# pma_tx_lane_registers: IP-XACT component
VLNV cadence:cdns_lib:pma_tx_lane_registers:1685-2009

## Address spaces and blocks
sd3101_t4_registers.sd3101_phy_registers: base 0x10000, range 0x7ff, width 32

## Registers
Registers are 32-bit, read-write, reset 0x0 unless marked. A register's access mark holds for its fields unless they carry their own. Offsets are from the block's base; lines under a group give offsets from that group; [hi:lo] are bit positions; {n}, {i} and the like mark numbered series; 'fields as' and 'values as' point back to an identical list; <NAME> marks a mode.

## sd3101_t4_registers.sd3101_phy_registers
Base 0x00010000
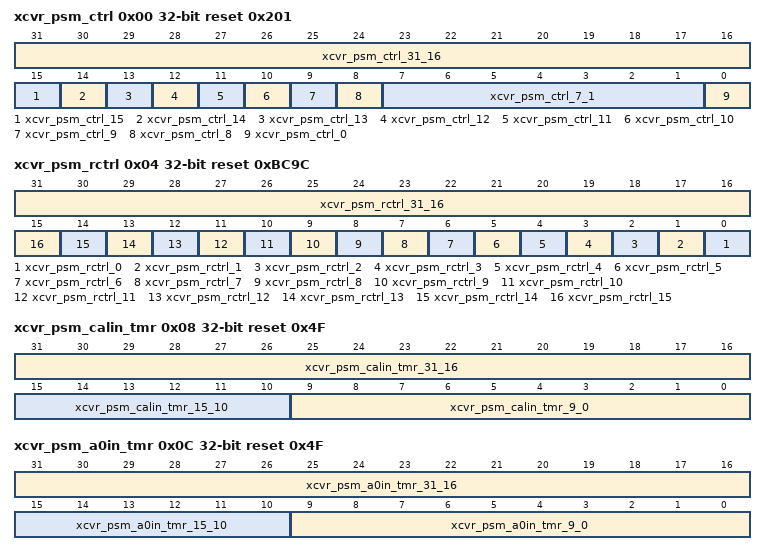
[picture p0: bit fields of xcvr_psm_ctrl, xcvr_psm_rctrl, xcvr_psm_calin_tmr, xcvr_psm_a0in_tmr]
0x00 xcvr_psm_ctrl reset 0x201 — Power state machine control register
  [31:16] xcvr_psm_ctrl_31_16 ro — Reserved
  [15] xcvr_psm_ctrl_15 ro — Reserved
  [14] xcvr_psm_ctrl_14
  [13] xcvr_psm_ctrl_13 — Bypass A0 in delay from A5
  [12] xcvr_psm_ctrl_12 — Bypass A0 in delay from A4
  [11] xcvr_psm_ctrl_11
  [10] xcvr_psm_ctrl_10 — Bypass A0 in delay from A2
  [9] xcvr_psm_ctrl_9 — Bypass A0 in delay from A1
  [8] xcvr_psm_ctrl_8 ro — Reserved
  [7:1] xcvr_psm_ctrl_7_1 ro — Reserved
  [0] xcvr_psm_ctrl_0
0x04 xcvr_psm_rctrl reset 0xBC9C — Power state machine reset control register
  [31:16] xcvr_psm_rctrl_31_16 ro — Reserved
  [n] xcvr_psm_rctrl_{n} (n=0..15)
0x08 xcvr_psm_calin_tmr reset 0x4F — PSM calibration in delay timer register
  [31:16] xcvr_psm_calin_tmr_31_16 ro — Reserved
  [15:10] xcvr_psm_calin_tmr_15_10 ro — Reserved
  [9:0] xcvr_psm_calin_tmr_9_0 — Note, the smallest value this field is allowed to be is 12'h001. With that said, setting this field to a value smaller than the reset value will likely result in incorrect function.
0x0C xcvr_psm_a0in_tmr reset 0x4F — A0 in delay timer register
  [31:16] xcvr_psm_a0in_tmr_31_16 ro — Reserved
  [15:10] xcvr_psm_a0in_tmr_15_10 ro — Reserved
  [9:0] xcvr_psm_a0in_tmr_9_0 — Note, the smallest value this field is allowed to be is 12'h001. With that said, setting this field to a value smaller than the reset value will likely result in incorrect function.
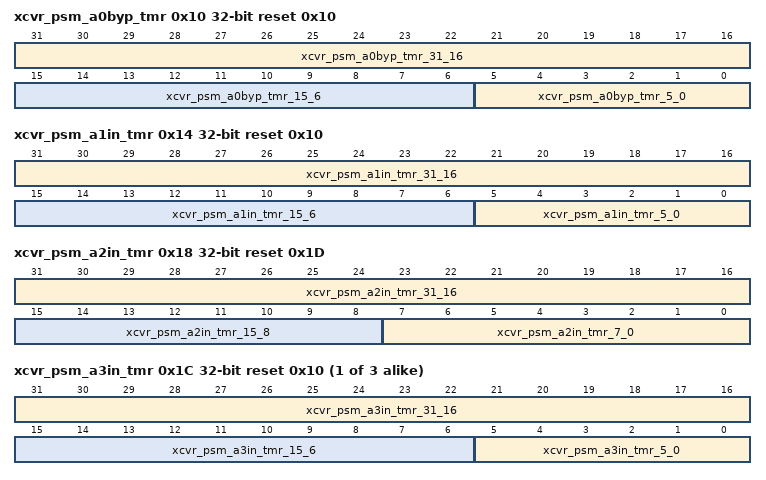
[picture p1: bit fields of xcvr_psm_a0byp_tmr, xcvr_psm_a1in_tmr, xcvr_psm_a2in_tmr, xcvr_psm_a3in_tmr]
0x10 xcvr_psm_a0byp_tmr reset 0x10 — A0 in bypass timer register
  [31:16] xcvr_psm_a0byp_tmr_31_16 ro — Reserved
  [15:6] xcvr_psm_a0byp_tmr_15_6 ro — Reserved
  [5:0] xcvr_psm_a0byp_tmr_5_0 — Note, the smallest value this field is allowed to be is 6'h01. With that said, setting this field to a value smaller than the reset value will likely result in incorrect function.
0x14 xcvr_psm_a1in_tmr reset 0x10 — A1 in delay timer register
  [31:16] xcvr_psm_a1in_tmr_31_16 ro — Reserved
  [15:6] xcvr_psm_a1in_tmr_15_6 ro — Reserved
  [5:0] xcvr_psm_a1in_tmr_5_0 — Note, the smallest value this field is allowed to be is 6'h01. With that said, setting this field to a value smaller than the reset value will likely result in incorrect function.
0x18 xcvr_psm_a2in_tmr reset 0x1D — A2 in delay timer register
  [31:16] xcvr_psm_a2in_tmr_31_16 ro — Reserved
  [15:8] xcvr_psm_a2in_tmr_15_8 ro — Reserved
  [7:0] xcvr_psm_a2in_tmr_7_0 — Note, the smallest value this field is allowed to be is 6'h01. With that said, setting this field to a value smaller than the reset value will likely result in incorrect function.
{0x10+4i} xcvr_psm_a{i}in_tmr reset 0x10 (i=3..5) — A{i} in delay timer register
  [31:16] xcvr_psm_a{i}in_tmr_31_16 ro — Reserved
  [15:6] xcvr_psm_a{i}in_tmr_15_6 ro — Reserved
  [5:0] xcvr_psm_a{i}in_tmr_5_0 — Note, the smallest value this field is allowed to be is 6'h01. With that said, setting this field to a value smaller than the reset value will likely result in incorrect function.
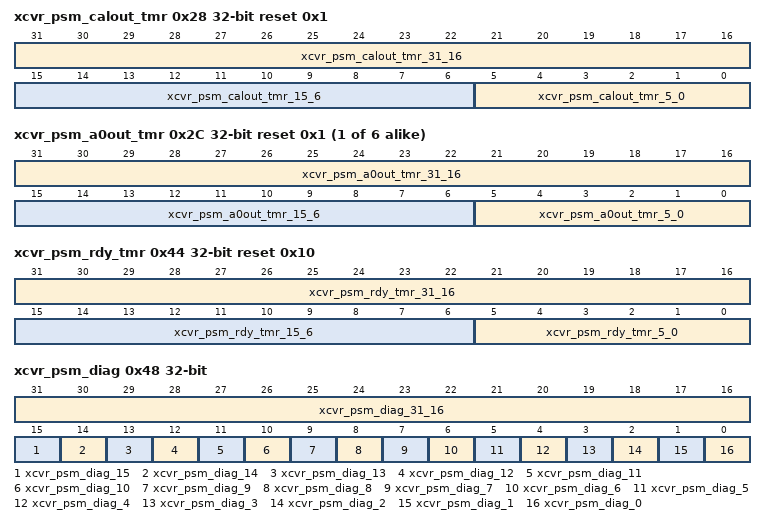
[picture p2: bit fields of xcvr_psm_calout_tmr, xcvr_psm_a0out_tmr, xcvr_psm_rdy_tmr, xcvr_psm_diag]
0x28 xcvr_psm_calout_tmr reset 0x1 — PSM calibration out delay timer register
  [31:16] xcvr_psm_calout_tmr_31_16 ro — Reserved
  [15:6] xcvr_psm_calout_tmr_15_6 ro — Reserved
  [5:0] xcvr_psm_calout_tmr_5_0 — Note, the smallest value this field is allowed to be is 6'h01. With that said, setting this field to a value smaller than the reset value will likely result in incorrect function.
{0x2C+4i} xcvr_psm_a{i}out_tmr reset 0x1 (i=0..5) — A{i} out delay timer register
  [31:16] xcvr_psm_a{i}out_tmr_31_16 ro — Reserved
  [15:6] xcvr_psm_a{i}out_tmr_15_6 ro — Reserved
  [5:0] xcvr_psm_a{i}out_tmr_5_0 — Note, the smallest value this field is allowed to be is 6'h01. With that said, setting this field to a value smaller than the reset value will likely result in incorrect function.
0x44 xcvr_psm_rdy_tmr reset 0x10 — Ready delay timer register
  [31:16] xcvr_psm_rdy_tmr_31_16 ro — Reserved
  [15:6] xcvr_psm_rdy_tmr_15_6 ro — Reserved
  [5:0] xcvr_psm_rdy_tmr_5_0 — Note, the smallest value this field is allowed to be is 6'h01. With that said, setting this field to a value smaller than the reset value will likely result in incorrect function.
0x48 xcvr_psm_diag — Power state machine diagnostic register
  [31:16] xcvr_psm_diag_31_16 ro — Reserved
  [15] xcvr_psm_diag_15 ro — Reserved
  [14] xcvr_psm_diag_14
  [13] xcvr_psm_diag_13 — Force A5 exit acknowledge
  [12] xcvr_psm_diag_12 — Force A4 exit acknowledge
  [11] xcvr_psm_diag_11
  [10] xcvr_psm_diag_10 — Force A2 exit acknowledge
  [9] xcvr_psm_diag_9 — Force A1 exit acknowledge
  [8] xcvr_psm_diag_8
  [7] xcvr_psm_diag_7 ro — Reserved
  [6] xcvr_psm_diag_6 — Force calibration entry acknowledge
  [5] xcvr_psm_diag_5 — Force A5 entry acknowledge
  [4] xcvr_psm_diag_4
  [3] xcvr_psm_diag_3 — Force A3 entry acknowledge
  [2] xcvr_psm_diag_2 — Force A2 entry acknowledge
  [1] xcvr_psm_diag_1
  [0] xcvr_psm_diag_0 — Force A0 entry acknowledge
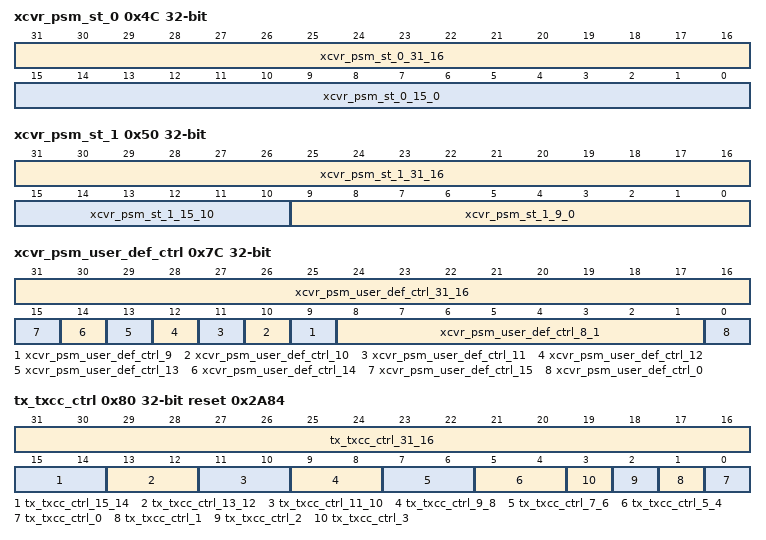
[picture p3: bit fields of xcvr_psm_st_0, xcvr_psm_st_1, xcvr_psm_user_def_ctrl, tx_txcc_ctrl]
0x4C xcvr_psm_st_0 — PSM current state register 0
  [31:16] xcvr_psm_st_0_31_16 ro — Reserved
  [15:0] xcvr_psm_st_0_15_0 ro — PSM current state[15:0]
0x50 xcvr_psm_st_1 — PSM current state register 1
  [31:16] xcvr_psm_st_1_31_16 ro — Reserved
  [15:10] xcvr_psm_st_1_15_10 ro — Reserved
  [9:0] xcvr_psm_st_1_9_0 ro — PSM current state[25:16]
0x7C xcvr_psm_user_def_ctrl — Power state machine user defined control register
  [31:16] xcvr_psm_user_def_ctrl_31_16 — Reserved - spare
  [n] xcvr_psm_user_def_ctrl_{n} (n=9..15)
  [8:1] xcvr_psm_user_def_ctrl_8_1 — Reserved - spare
  [0] xcvr_psm_user_def_ctrl_0
0x80 tx_txcc_ctrl reset 0x2A84 — TX coefficient controller control register
  [31:16] tx_txcc_ctrl_31_16 ro — Reserved
  [15:14] tx_txcc_ctrl_15_14 ro — Reserved
  [13:12] tx_txcc_ctrl_13_12
  [11:10] tx_txcc_ctrl_11_10
  [9:8] tx_txcc_ctrl_9_8
  [7:6] tx_txcc_ctrl_7_6
  [5:4] tx_txcc_ctrl_5_4
  [n] tx_txcc_ctrl_{n} (n=0..3)
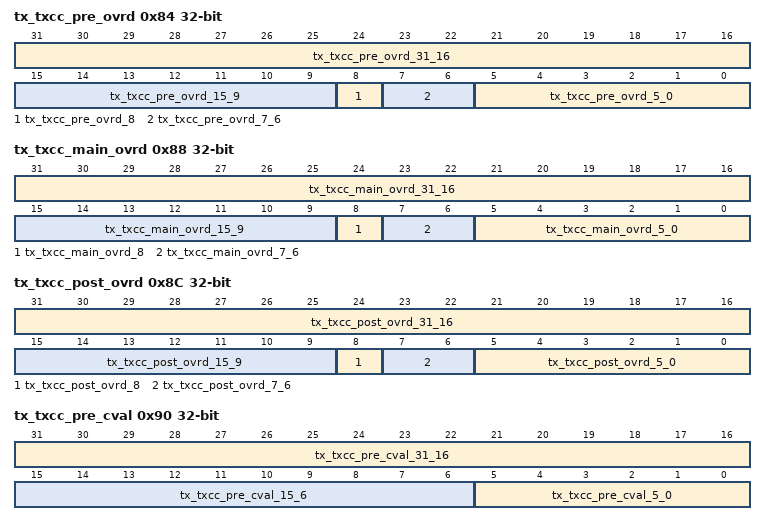
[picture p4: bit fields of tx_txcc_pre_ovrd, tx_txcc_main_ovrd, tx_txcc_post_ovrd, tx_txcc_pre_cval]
0x84 tx_txcc_pre_ovrd — TX pre-cursor override register
  [31:16] tx_txcc_pre_ovrd_31_16 ro — Reserved
  [15:9] tx_txcc_pre_ovrd_15_9 ro — Reserved
  [8] tx_txcc_pre_ovrd_8 — Pre-cursor override enable
  [7:6] tx_txcc_pre_ovrd_7_6 ro — Reserved
  [5:0] tx_txcc_pre_ovrd_5_0
0x88 tx_txcc_main_ovrd — TX main-cursor override register
  [31:16] tx_txcc_main_ovrd_31_16 ro — Reserved
  [15:9] tx_txcc_main_ovrd_15_9 ro — Reserved
  [8] tx_txcc_main_ovrd_8 — Main-cursor override enable
  [7:6] tx_txcc_main_ovrd_7_6 ro — Reserved
  [5:0] tx_txcc_main_ovrd_5_0
0x8C tx_txcc_post_ovrd — TX post-cursor override register
  [31:16] tx_txcc_post_ovrd_31_16 ro — Reserved
  [15:9] tx_txcc_post_ovrd_15_9 ro — Reserved
  [8] tx_txcc_post_ovrd_8 — Post-cursor override enable
  [7:6] tx_txcc_post_ovrd_7_6 ro — Reserved
  [5:0] tx_txcc_post_ovrd_5_0
0x90 tx_txcc_pre_cval — TX pre-cursor current value register
  [31:16] tx_txcc_pre_cval_31_16 ro — Reserved
  [15:6] tx_txcc_pre_cval_15_6 ro — Reserved
  [5:0] tx_txcc_pre_cval_5_0 ro
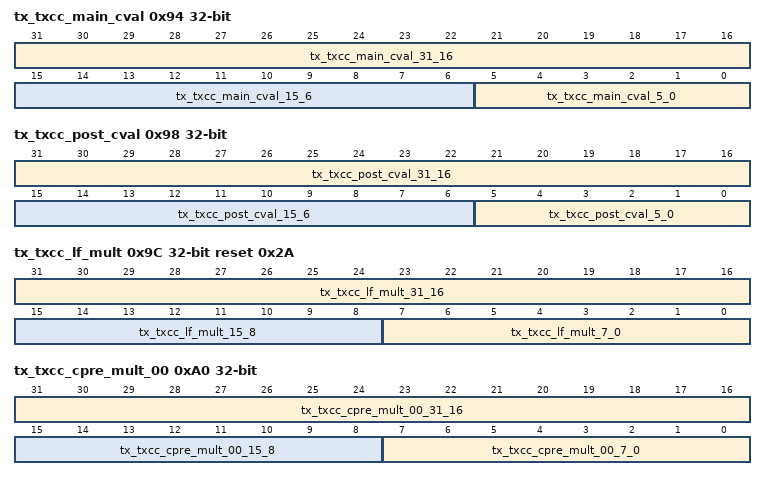
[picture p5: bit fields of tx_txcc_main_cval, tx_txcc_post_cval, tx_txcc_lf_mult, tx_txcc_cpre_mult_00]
0x94 tx_txcc_main_cval — TX main-cursor current value register
  [31:16] tx_txcc_main_cval_31_16 ro — Reserved
  [15:6] tx_txcc_main_cval_15_6 ro — Reserved
  [5:0] tx_txcc_main_cval_5_0 ro
0x98 tx_txcc_post_cval — TX post-cursor current value register
  [31:16] tx_txcc_post_cval_31_16 ro — Reserved
  [15:6] tx_txcc_post_cval_15_6 ro — Reserved
  [5:0] tx_txcc_post_cval_5_0 ro
0x9C tx_txcc_lf_mult reset 0x2A — LF multiplier value register
  [31:16] tx_txcc_lf_mult_31_16 ro — Reserved
  [15:8] tx_txcc_lf_mult_15_8 ro — Reserved
  [7:0] tx_txcc_lf_mult_7_0 — Note: The output of the multiplier is 6 bits wide. It is possible to set the multiplier value here to a sufficiently large value to cause the multiplier result to be such that it can't be represented by a 6 bit value. In such a case, the multiplier output will be driven to 6'b111111.
0xA0 tx_txcc_cpre_mult_00 — Calculated pre emphasis multiplier value 00 register
  [31:16] tx_txcc_cpre_mult_00_31_16 ro — Reserved
  [15:8] tx_txcc_cpre_mult_00_15_8 ro — Reserved
  [7:0] tx_txcc_cpre_mult_00_7_0 — Note: The output of the multiplier is 6 bits wide. It is possible to set the multiplier value here to a sufficiently large value to cause the multiplier result to be such that it can't be represented by a 6 bit value. In such a case, the multiplier output will be driven to 6'b111111.
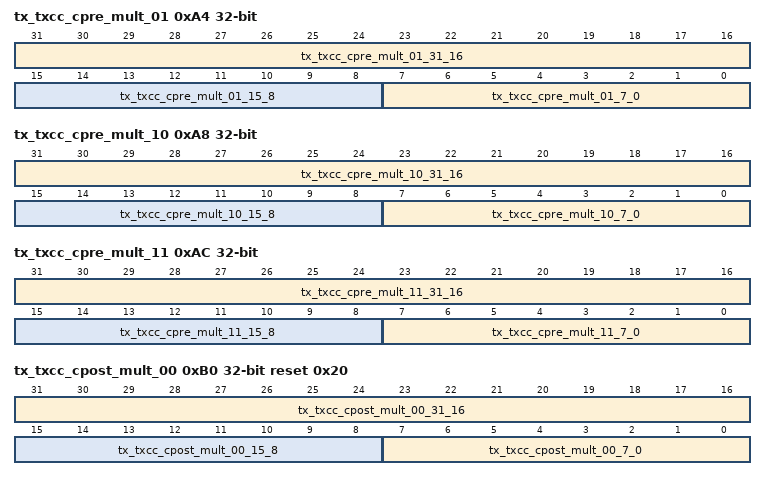
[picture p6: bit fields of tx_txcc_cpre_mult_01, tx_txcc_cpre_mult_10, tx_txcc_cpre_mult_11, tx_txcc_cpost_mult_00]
0xA4 tx_txcc_cpre_mult_01 — Calculated pre emphasis multiplier value 01 register
  [31:16] tx_txcc_cpre_mult_01_31_16 ro — Reserved
  [15:8] tx_txcc_cpre_mult_01_15_8 ro — Reserved
  [7:0] tx_txcc_cpre_mult_01_7_0 — Note: The output of the multiplier is 6 bits wide. It is possible to set the multiplier value here to a sufficiently large value to cause the multiplier result to be such that it can't be represented by a 6 bit value. In such a case, the multiplier output will be driven to 6'b111111.
0xA8 tx_txcc_cpre_mult_10 — Calculated pre emphasis multiplier value 10 register
  [31:16] tx_txcc_cpre_mult_10_31_16 ro — Reserved
  [15:8] tx_txcc_cpre_mult_10_15_8 ro — Reserved
  [7:0] tx_txcc_cpre_mult_10_7_0 — Note: The output of the multiplier is 6 bits wide. It is possible to set the multiplier value here to a sufficiently large value to cause the multiplier result to be such that it can't be represented by a 6 bit value. In such a case, the multiplier output will be driven to 6'b111111.
0xAC tx_txcc_cpre_mult_11 — Calculated pre emphasis multiplier value 11 register
  [31:16] tx_txcc_cpre_mult_11_31_16 ro — Reserved
  [15:8] tx_txcc_cpre_mult_11_15_8 ro — Reserved
  [7:0] tx_txcc_cpre_mult_11_7_0 — Note: The output of the multiplier is 6 bits wide. It is possible to set the multiplier value here to a sufficiently large value to cause the multiplier result to be such that it can't be represented by a 6 bit value. In such a case, the multiplier output will be driven to 6'b111111.
0xB0 tx_txcc_cpost_mult_00 reset 0x20 — Calculated post emphasis multiplier value 00 register
  [31:16] tx_txcc_cpost_mult_00_31_16 ro — Reserved
  [15:8] tx_txcc_cpost_mult_00_15_8 ro — Reserved
  [7:0] tx_txcc_cpost_mult_00_7_0 — Note: The output of the multiplier is 6 bits wide. It is possible to set the multiplier value here to a sufficiently large value to cause the multiplier result to be such that it can't be represented by a 6 bit value. In such a case, the multiplier output will be driven to 6'b111111.
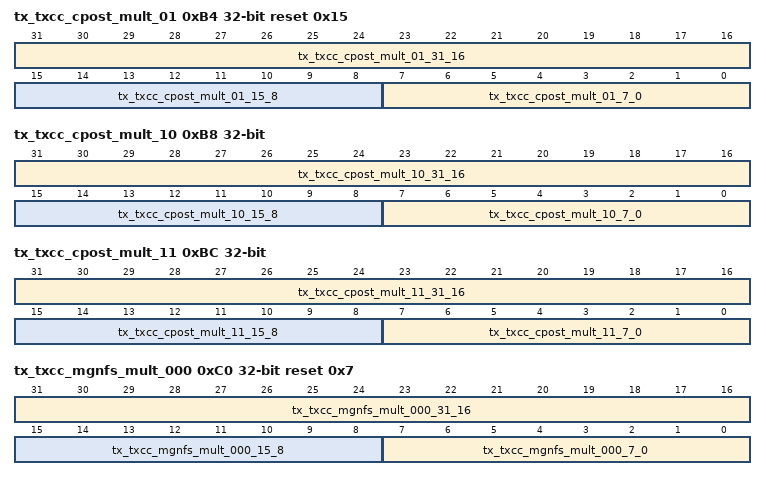
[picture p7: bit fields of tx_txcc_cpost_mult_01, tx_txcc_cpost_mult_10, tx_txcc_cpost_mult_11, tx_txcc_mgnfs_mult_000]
0xB4 tx_txcc_cpost_mult_01 reset 0x15 — Calculated post emphasis multiplier value 01 register
  [31:16] tx_txcc_cpost_mult_01_31_16 ro — Reserved
  [15:8] tx_txcc_cpost_mult_01_15_8 ro — Reserved
  [7:0] tx_txcc_cpost_mult_01_7_0 — Note: The output of the multiplier is 6 bits wide. It is possible to set the multiplier value here to a sufficiently large value to cause the multiplier result to be such that it can't be represented by a 6 bit value. In such a case, the multiplier output will be driven to 6'b111111.
0xB8 tx_txcc_cpost_mult_10 — Calculated post emphasis multiplier value 10 register
  [31:16] tx_txcc_cpost_mult_10_31_16 ro — Reserved
  [15:8] tx_txcc_cpost_mult_10_15_8 ro — Reserved
  [7:0] tx_txcc_cpost_mult_10_7_0 — Note: The output of the multiplier is 6 bits wide. It is possible to set the multiplier value here to a sufficiently large value to cause the multiplier result to be such that it can't be represented by a 6 bit value. In such a case, the multiplier output will be driven to 6'b111111.
0xBC tx_txcc_cpost_mult_11 — Calculated post emphasis multiplier value 11 register
  [31:16] tx_txcc_cpost_mult_11_31_16 ro — Reserved
  [15:8] tx_txcc_cpost_mult_11_15_8 ro — Reserved
  [7:0] tx_txcc_cpost_mult_11_7_0 — Note: The output of the multiplier is 6 bits wide. It is possible to set the multiplier value here to a sufficiently large value to cause the multiplier result to be such that it can't be represented by a 6 bit value. In such a case, the multiplier output will be driven to 6'b111111.
0xC0 tx_txcc_mgnfs_mult_000 reset 0x7 — Margin full swing multiplier value 000 register
  [31:16] tx_txcc_mgnfs_mult_000_31_16 ro — Reserved
  [15:8] tx_txcc_mgnfs_mult_000_15_8 ro — Reserved
  [7:0] tx_txcc_mgnfs_mult_000_7_0 — Note: The output of the multiplier is 6 bits wide. It is possible to set the multiplier value here to a sufficiently large value to cause the multiplier result to be such that it can't be represented by a 6 bit value. In such a case, the multiplier output will be driven to 6'b111111.
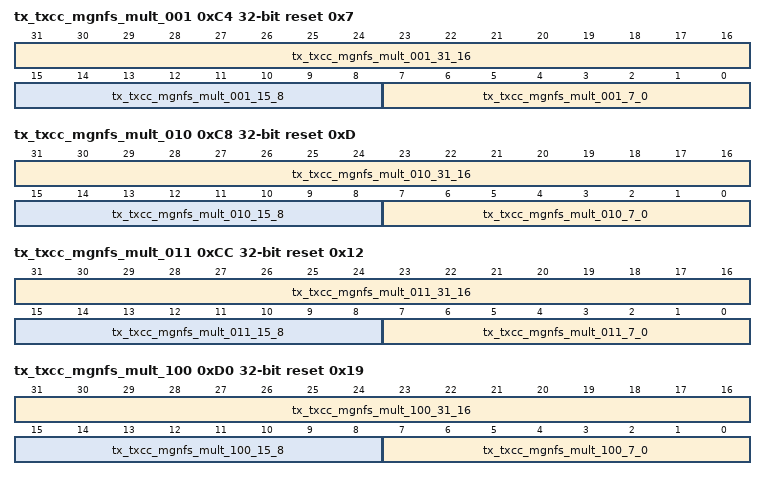
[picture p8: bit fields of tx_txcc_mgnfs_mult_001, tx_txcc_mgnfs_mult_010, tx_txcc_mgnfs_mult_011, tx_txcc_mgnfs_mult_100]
0xC4 tx_txcc_mgnfs_mult_001 reset 0x7 — Margin full swing multiplier value 001 register
  [31:16] tx_txcc_mgnfs_mult_001_31_16 ro — Reserved
  [15:8] tx_txcc_mgnfs_mult_001_15_8 ro — Reserved
  [7:0] tx_txcc_mgnfs_mult_001_7_0 — Note: The output of the multiplier is 6 bits wide. It is possible to set the multiplier value here to a sufficiently large value to cause the multiplier result to be such that it can't be represented by a 6 bit value. In such a case, the multiplier output will be driven to 6'b111111.
0xC8 tx_txcc_mgnfs_mult_010 reset 0xD — Margin full swing multiplier value 010 register
  [31:16] tx_txcc_mgnfs_mult_010_31_16 ro — Reserved
  [15:8] tx_txcc_mgnfs_mult_010_15_8 ro — Reserved
  [7:0] tx_txcc_mgnfs_mult_010_7_0 — Note: The output of the multiplier is 6 bits wide. It is possible to set the multiplier value here to a sufficiently large value to cause the multiplier result to be such that it can't be represented by a 6 bit value. In such a case, the multiplier output will be driven to 6'b111111.
0xCC tx_txcc_mgnfs_mult_011 reset 0x12 — Margin full swing multiplier value 011 register
  [31:16] tx_txcc_mgnfs_mult_011_31_16 ro — Reserved
  [15:8] tx_txcc_mgnfs_mult_011_15_8 ro — Reserved
  [7:0] tx_txcc_mgnfs_mult_011_7_0 — Note: The output of the multiplier is 6 bits wide. It is possible to set the multiplier value here to a sufficiently large value to cause the multiplier result to be such that it can't be represented by a 6 bit value. In such a case, the multiplier output will be driven to 6'b111111.
0xD0 tx_txcc_mgnfs_mult_100 reset 0x19 — Margin full swing multiplier value 100 register
  [31:16] tx_txcc_mgnfs_mult_100_31_16 ro — Reserved
  [15:8] tx_txcc_mgnfs_mult_100_15_8 ro — Reserved
  [7:0] tx_txcc_mgnfs_mult_100_7_0 — Note: The output of the multiplier is 6 bits wide. It is possible to set the multiplier value here to a sufficiently large value to cause the multiplier result to be such that it can't be represented by a 6 bit value. In such a case, the multiplier output will be driven to 6'b111111.
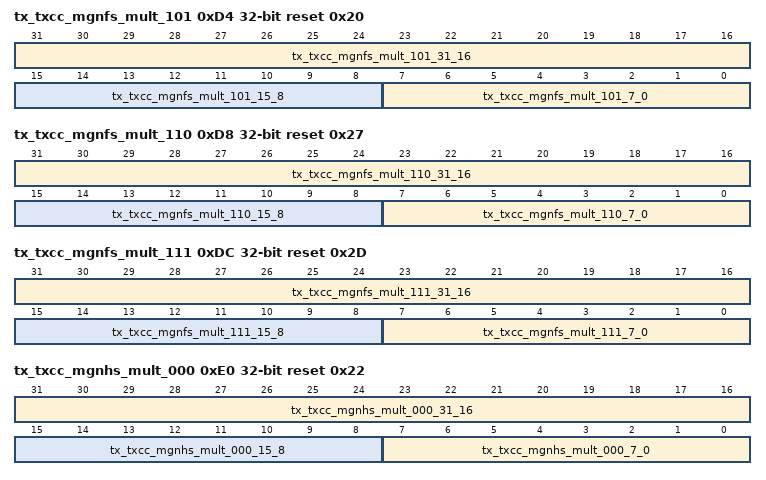
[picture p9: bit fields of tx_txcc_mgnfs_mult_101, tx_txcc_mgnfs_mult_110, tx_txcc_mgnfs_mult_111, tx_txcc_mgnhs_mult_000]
0xD4 tx_txcc_mgnfs_mult_101 reset 0x20 — Margin full swing multiplier value 101 register
  [31:16] tx_txcc_mgnfs_mult_101_31_16 ro — Reserved
  [15:8] tx_txcc_mgnfs_mult_101_15_8 ro — Reserved
  [7:0] tx_txcc_mgnfs_mult_101_7_0 — Note: The output of the multiplier is 6 bits wide. It is possible to set the multiplier value here to a sufficiently large value to cause the multiplier result to be such that it can't be represented by a 6 bit value. In such a case, the multiplier output will be driven to 6'b111111.
0xD8 tx_txcc_mgnfs_mult_110 reset 0x27 — Margin full swing multiplier value 110 register
  [31:16] tx_txcc_mgnfs_mult_110_31_16 ro — Reserved
  [15:8] tx_txcc_mgnfs_mult_110_15_8 ro — Reserved
  [7:0] tx_txcc_mgnfs_mult_110_7_0 — Note: The output of the multiplier is 6 bits wide. It is possible to set the multiplier value here to a sufficiently large value to cause the multiplier result to be such that it can't be represented by a 6 bit value. In such a case, the multiplier output will be driven to 6'b111111.
0xDC tx_txcc_mgnfs_mult_111 reset 0x2D — Margin full swing multiplier value 111 register
  [31:16] tx_txcc_mgnfs_mult_111_31_16 ro — Reserved
  [15:8] tx_txcc_mgnfs_mult_111_15_8 ro — Reserved
  [7:0] tx_txcc_mgnfs_mult_111_7_0 — Note: The output of the multiplier is 6 bits wide. It is possible to set the multiplier value here to a sufficiently large value to cause the multiplier result to be such that it can't be represented by a 6 bit value. In such a case, the multiplier output will be driven to 6'b111111.
0xE0 tx_txcc_mgnhs_mult_000 reset 0x22 — Margin half swing multiplier value 000 register
  [31:16] tx_txcc_mgnhs_mult_000_31_16 ro — Reserved
  [15:8] tx_txcc_mgnhs_mult_000_15_8 ro — Reserved
  [7:0] tx_txcc_mgnhs_mult_000_7_0 — Note: The output of the multiplier is 6 bits wide. It is possible to set the multiplier value here to a sufficiently large value to cause the multiplier result to be such that it can't be represented by a 6 bit value. In such a case, the multiplier output will be driven to 6'b111111.
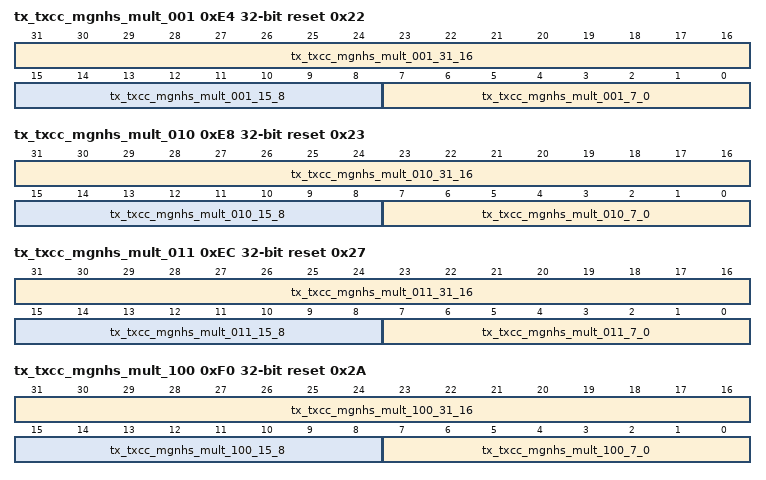
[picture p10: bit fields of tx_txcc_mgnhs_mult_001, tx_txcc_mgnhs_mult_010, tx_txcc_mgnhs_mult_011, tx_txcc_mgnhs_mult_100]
0xE4 tx_txcc_mgnhs_mult_001 reset 0x22 — Margin half swing multiplier value 001 register
  [31:16] tx_txcc_mgnhs_mult_001_31_16 ro — Reserved
  [15:8] tx_txcc_mgnhs_mult_001_15_8 ro — Reserved
  [7:0] tx_txcc_mgnhs_mult_001_7_0 — Note: The output of the multiplier is 6 bits wide. It is possible to set the multiplier value here to a sufficiently large value to cause the multiplier result to be such that it can't be represented by a 6 bit value. In such a case, the multiplier output will be driven to 6'b111111.
0xE8 tx_txcc_mgnhs_mult_010 reset 0x23 — Margin half swing multiplier value 010 register
  [31:16] tx_txcc_mgnhs_mult_010_31_16 ro — Reserved
  [15:8] tx_txcc_mgnhs_mult_010_15_8 ro — Reserved
  [7:0] tx_txcc_mgnhs_mult_010_7_0 — Note: The output of the multiplier is 6 bits wide. It is possible to set the multiplier value here to a sufficiently large value to cause the multiplier result to be such that it can't be represented by a 6 bit value. In such a case, the multiplier output will be driven to 6'b111111.
0xEC tx_txcc_mgnhs_mult_011 reset 0x27 — Margin half swing multiplier value 011 register
  [31:16] tx_txcc_mgnhs_mult_011_31_16 ro — Reserved
  [15:8] tx_txcc_mgnhs_mult_011_15_8 ro — Reserved
  [7:0] tx_txcc_mgnhs_mult_011_7_0 — Note: The output of the multiplier is 6 bits wide. It is possible to set the multiplier value here to a sufficiently large value to cause the multiplier result to be such that it can't be represented by a 6 bit value. In such a case, the multiplier output will be driven to 6'b111111.
0xF0 tx_txcc_mgnhs_mult_100 reset 0x2A — Margin half swing multiplier value 100 register
  [31:16] tx_txcc_mgnhs_mult_100_31_16 ro — Reserved
  [15:8] tx_txcc_mgnhs_mult_100_15_8 ro — Reserved
  [7:0] tx_txcc_mgnhs_mult_100_7_0 — Note: The output of the multiplier is 6 bits wide. It is possible to set the multiplier value here to a sufficiently large value to cause the multiplier result to be such that it can't be represented by a 6 bit value. In such a case, the multiplier output will be driven to 6'b111111.
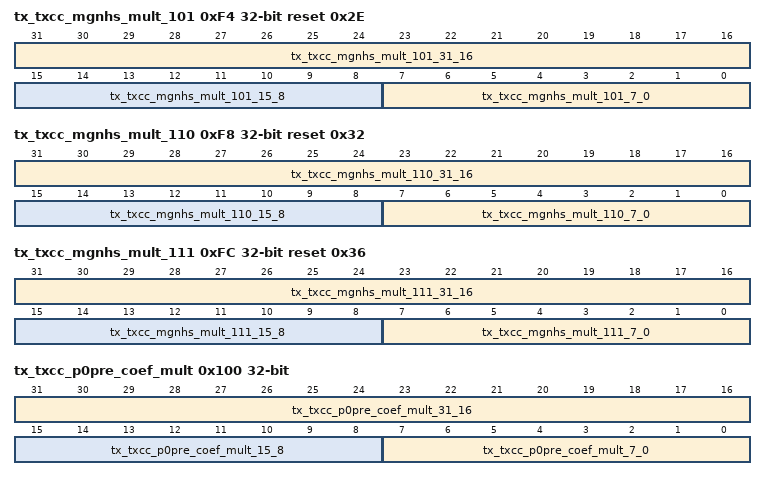
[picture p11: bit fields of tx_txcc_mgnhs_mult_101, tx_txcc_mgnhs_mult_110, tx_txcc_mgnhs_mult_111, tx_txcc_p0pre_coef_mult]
0xF4 tx_txcc_mgnhs_mult_101 reset 0x2E — Margin half swing multiplier value 101 register
  [31:16] tx_txcc_mgnhs_mult_101_31_16 ro — Reserved
  [15:8] tx_txcc_mgnhs_mult_101_15_8 ro — Reserved
  [7:0] tx_txcc_mgnhs_mult_101_7_0 — Note: The output of the multiplier is 6 bits wide. It is possible to set the multiplier value here to a sufficiently large value to cause the multiplier result to be such that it can't be represented by a 6 bit value. In such a case, the multiplier output will be driven to 6'b111111.
0xF8 tx_txcc_mgnhs_mult_110 reset 0x32 — Margin half swing multiplier value 110 register
  [31:16] tx_txcc_mgnhs_mult_110_31_16 ro — Reserved
  [15:8] tx_txcc_mgnhs_mult_110_15_8 ro — Reserved
  [7:0] tx_txcc_mgnhs_mult_110_7_0 — Note: The output of the multiplier is 6 bits wide. It is possible to set the multiplier value here to a sufficiently large value to cause the multiplier result to be such that it can't be represented by a 6 bit value. In such a case, the multiplier output will be driven to 6'b111111.
0xFC tx_txcc_mgnhs_mult_111 reset 0x36 — Margin half swing multiplier value 111 register
  [31:16] tx_txcc_mgnhs_mult_111_31_16 ro — Reserved
  [15:8] tx_txcc_mgnhs_mult_111_15_8 ro — Reserved
  [7:0] tx_txcc_mgnhs_mult_111_7_0 — Note: The output of the multiplier is 6 bits wide. It is possible to set the multiplier value here to a sufficiently large value to cause the multiplier result to be such that it can't be represented by a 6 bit value. In such a case, the multiplier output will be driven to 6'b111111.
0x100 tx_txcc_p0pre_coef_mult — Preset 0 pre emphasis coefficient multiplier value register
  [31:16] tx_txcc_p0pre_coef_mult_31_16 ro — Reserved
  [15:8] tx_txcc_p0pre_coef_mult_15_8 ro — Reserved
  [7:0] tx_txcc_p0pre_coef_mult_7_0 — Note: The output of the multiplier is 6 bits wide. It is possible to set the multiplier value here to a sufficiently large value to cause the multiplier result to be such that it can't be represented by a 6 bit value. In such a case, the multiplier output will be driven to 6'b111111.
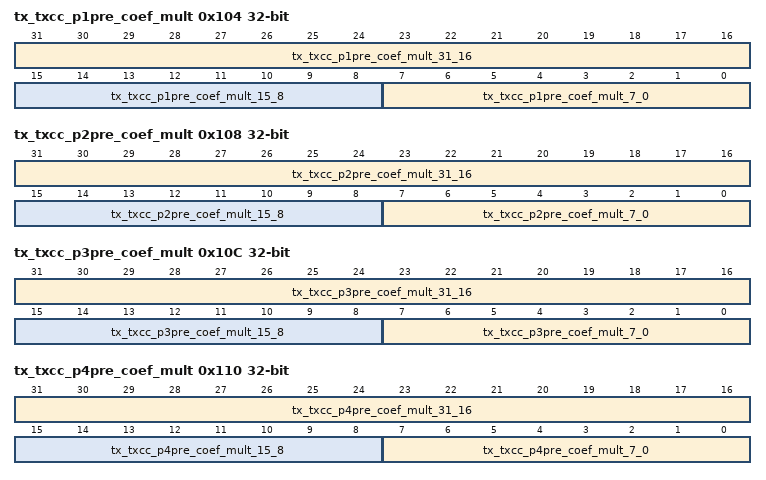
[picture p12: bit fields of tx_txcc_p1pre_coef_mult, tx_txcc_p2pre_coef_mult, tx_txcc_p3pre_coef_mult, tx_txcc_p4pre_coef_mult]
0x104 tx_txcc_p1pre_coef_mult — Preset 1 pre emphasis coefficient multiplier value register
  [31:16] tx_txcc_p1pre_coef_mult_31_16 ro — Reserved
  [15:8] tx_txcc_p1pre_coef_mult_15_8 ro — Reserved
  [7:0] tx_txcc_p1pre_coef_mult_7_0 — Note: The output of the multiplier is 6 bits wide. It is possible to set the multiplier value here to a sufficiently large value to cause the multiplier result to be such that it can't be represented by a 6 bit value. In such a case, the multiplier output will be driven to 6'b111111.
0x108 tx_txcc_p2pre_coef_mult — Preset 2 pre emphasis coefficient multiplier value register
  [31:16] tx_txcc_p2pre_coef_mult_31_16 ro — Reserved
  [15:8] tx_txcc_p2pre_coef_mult_15_8 ro — Reserved
  [7:0] tx_txcc_p2pre_coef_mult_7_0 — Note: The output of the multiplier is 6 bits wide. It is possible to set the multiplier value here to a sufficiently large value to cause the multiplier result to be such that it can't be represented by a 6 bit value. In such a case, the multiplier output will be driven to 6'b111111.
0x10C tx_txcc_p3pre_coef_mult — Preset 3 pre emphasis coefficient multiplier value register
  [31:16] tx_txcc_p3pre_coef_mult_31_16 ro — Reserved
  [15:8] tx_txcc_p3pre_coef_mult_15_8 ro — Reserved
  [7:0] tx_txcc_p3pre_coef_mult_7_0 — Note: The output of the multiplier is 6 bits wide. It is possible to set the multiplier value here to a sufficiently large value to cause the multiplier result to be such that it can't be represented by a 6 bit value. In such a case, the multiplier output will be driven to 6'b111111.
0x110 tx_txcc_p4pre_coef_mult — Preset 4 pre emphasis coefficient multiplier value register
  [31:16] tx_txcc_p4pre_coef_mult_31_16 ro — Reserved
  [15:8] tx_txcc_p4pre_coef_mult_15_8 ro — Reserved
  [7:0] tx_txcc_p4pre_coef_mult_7_0 — Note: The output of the multiplier is 6 bits wide. It is possible to set the multiplier value here to a sufficiently large value to cause the multiplier result to be such that it can't be represented by a 6 bit value. In such a case, the multiplier output will be driven to 6'b111111.
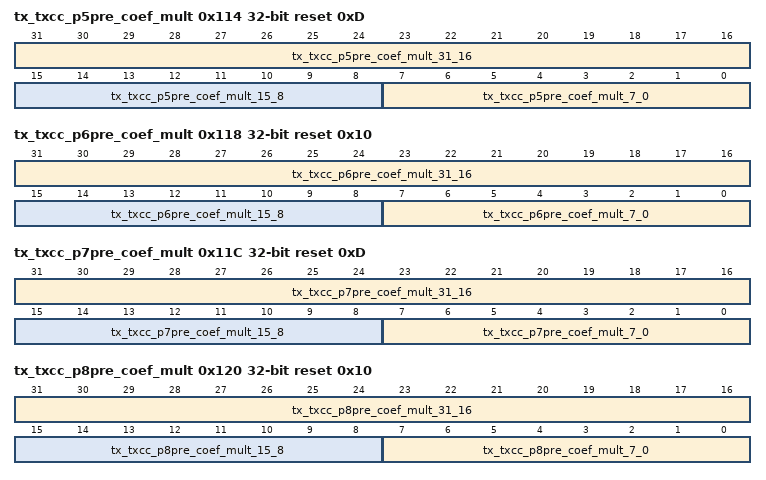
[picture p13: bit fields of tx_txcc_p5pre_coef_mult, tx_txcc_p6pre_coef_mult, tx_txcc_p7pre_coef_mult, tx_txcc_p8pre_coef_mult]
0x114 tx_txcc_p5pre_coef_mult reset 0xD — Preset 5 pre emphasis coefficient multiplier value register
  [31:16] tx_txcc_p5pre_coef_mult_31_16 ro — Reserved
  [15:8] tx_txcc_p5pre_coef_mult_15_8 ro — Reserved
  [7:0] tx_txcc_p5pre_coef_mult_7_0 — Note: The output of the multiplier is 6 bits wide. It is possible to set the multiplier value here to a sufficiently large value to cause the multiplier result to be such that it can't be represented by a 6 bit value. In such a case, the multiplier output will be driven to 6'b111111.
0x118 tx_txcc_p6pre_coef_mult reset 0x10 — Preset 6 pre emphasis coefficient multiplier value register
  [31:16] tx_txcc_p6pre_coef_mult_31_16 ro — Reserved
  [15:8] tx_txcc_p6pre_coef_mult_15_8 ro — Reserved
  [7:0] tx_txcc_p6pre_coef_mult_7_0 — Note: The output of the multiplier is 6 bits wide. It is possible to set the multiplier value here to a sufficiently large value to cause the multiplier result to be such that it can't be represented by a 6 bit value. In such a case, the multiplier output will be driven to 6'b111111.
0x11C tx_txcc_p7pre_coef_mult reset 0xD — Preset 7 pre emphasis coefficient multiplier value register
  [31:16] tx_txcc_p7pre_coef_mult_31_16 ro — Reserved
  [15:8] tx_txcc_p7pre_coef_mult_15_8 ro — Reserved
  [7:0] tx_txcc_p7pre_coef_mult_7_0 — Note: The output of the multiplier is 6 bits wide. It is possible to set the multiplier value here to a sufficiently large value to cause the multiplier result to be such that it can't be represented by a 6 bit value. In such a case, the multiplier output will be driven to 6'b111111.
0x120 tx_txcc_p8pre_coef_mult reset 0x10 — Preset 8 pre emphasis coefficient multiplier value register
  [31:16] tx_txcc_p8pre_coef_mult_31_16 ro — Reserved
  [15:8] tx_txcc_p8pre_coef_mult_15_8 ro — Reserved
  [7:0] tx_txcc_p8pre_coef_mult_7_0 — Note: The output of the multiplier is 6 bits wide. It is possible to set the multiplier value here to a sufficiently large value to cause the multiplier result to be such that it can't be represented by a 6 bit value. In such a case, the multiplier output will be driven to 6'b111111.
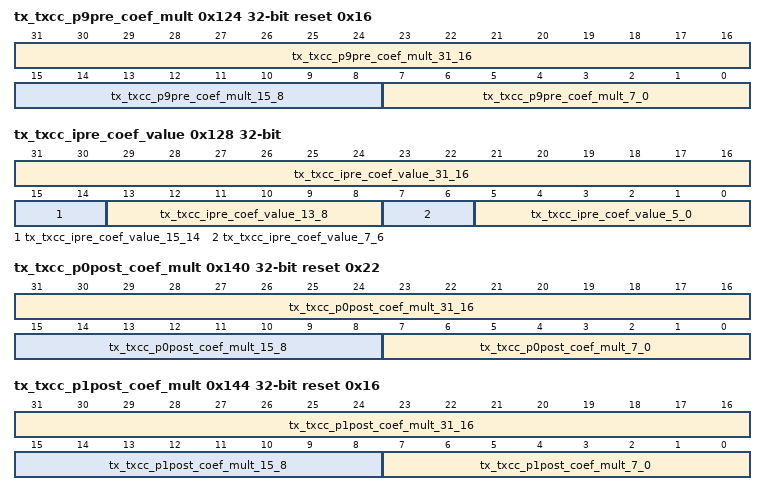
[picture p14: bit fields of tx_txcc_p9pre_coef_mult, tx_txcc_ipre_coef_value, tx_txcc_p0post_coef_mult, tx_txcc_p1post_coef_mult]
0x124 tx_txcc_p9pre_coef_mult reset 0x16 — Preset 9 pre emphasis coefficient multiplier value register
  [31:16] tx_txcc_p9pre_coef_mult_31_16 ro — Reserved
  [15:8] tx_txcc_p9pre_coef_mult_15_8 ro — Reserved
  [7:0] tx_txcc_p9pre_coef_mult_7_0 — Note: The output of the multiplier is 6 bits wide. It is possible to set the multiplier value here to a sufficiently large value to cause the multiplier result to be such that it can't be represented by a 6 bit value. In such a case, the multiplier output will be driven to 6'b111111.
0x128 tx_txcc_ipre_coef_value — Init pre emphasis coefficient value register
  [31:16] tx_txcc_ipre_coef_value_31_16 ro — Reserved
  [15:14] tx_txcc_ipre_coef_value_15_14 ro — Reserved
  [13:8] tx_txcc_ipre_coef_value_13_8
  [7:6] tx_txcc_ipre_coef_value_7_6 ro — Reserved
  [5:0] tx_txcc_ipre_coef_value_5_0
0x140 tx_txcc_p0post_coef_mult reset 0x22 — Preset 0 post emphasis coefficient multiplier value register
  [31:16] tx_txcc_p0post_coef_mult_31_16 ro — Reserved
  [15:8] tx_txcc_p0post_coef_mult_15_8 ro — Reserved
  [7:0] tx_txcc_p0post_coef_mult_7_0 — Note: The output of the multiplier is 6 bits wide. It is possible to set the multiplier value here to a sufficiently large value to cause the multiplier result to be such that it can't be represented by a 6 bit value. In such a case, the multiplier output will be driven to 6'b111111.
0x144 tx_txcc_p1post_coef_mult reset 0x16 — Preset 1 post emphasis coefficient multiplier value register
  [31:16] tx_txcc_p1post_coef_mult_31_16 ro — Reserved
  [15:8] tx_txcc_p1post_coef_mult_15_8 ro — Reserved
  [7:0] tx_txcc_p1post_coef_mult_7_0 — Note: The output of the multiplier is 6 bits wide. It is possible to set the multiplier value here to a sufficiently large value to cause the multiplier result to be such that it can't be represented by a 6 bit value. In such a case, the multiplier output will be driven to 6'b111111.
0x148 tx_txcc_p2post_coef_mult reset 0x19 — Preset 2 post emphasis coefficient multiplier value register
  [31:16] tx_txcc_p2post_coef_mult_31_16 ro — Reserved
  [15:8] tx_txcc_p2post_coef_mult_15_8 ro — Reserved
  [7:0] tx_txcc_p2post_coef_mult_7_0 — Note: The output of the multiplier is 6 bits wide. It is possible to set the multiplier value here to a sufficiently large value to cause the multiplier result to be such that it can't be represented by a 6 bit value. In such a case, the multiplier output will be driven to 6'b111111.
0x14C tx_txcc_p3post_coef_mult reset 0x10 — Preset 3 post emphasis coefficient multiplier value register
  [31:16] tx_txcc_p3post_coef_mult_31_16 ro — Reserved
  [15:8] tx_txcc_p3post_coef_mult_15_8 ro — Reserved
  [7:0] tx_txcc_p3post_coef_mult_7_0 — Note: The output of the multiplier is 6 bits wide. It is possible to set the multiplier value here to a sufficiently large value to cause the multiplier result to be such that it can't be represented by a 6 bit value. In such a case, the multiplier output will be driven to 6'b111111.
0x150 tx_txcc_p4post_coef_mult — Preset 4 post emphasis coefficient multiplier value register
  [31:16] tx_txcc_p4post_coef_mult_31_16 ro — Reserved
  [15:8] tx_txcc_p4post_coef_mult_15_8 ro — Reserved
  [7:0] tx_txcc_p4post_coef_mult_7_0 — Note: The output of the multiplier is 6 bits wide. It is possible to set the multiplier value here to a sufficiently large value to cause the multiplier result to be such that it can't be represented by a 6 bit value. In such a case, the multiplier output will be driven to 6'b111111.
0x154 tx_txcc_p5post_coef_mult — Preset 5 post emphasis coefficient multiplier value register
  [31:16] tx_txcc_p5post_coef_mult_31_16 ro — Reserved
  [15:8] tx_txcc_p5post_coef_mult_15_8 ro — Reserved
  [7:0] tx_txcc_p5post_coef_mult_7_0 — Note: The output of the multiplier is 6 bits wide. It is possible to set the multiplier value here to a sufficiently large value to cause the multiplier result to be such that it can't be represented by a 6 bit value. In such a case, the multiplier output will be driven to 6'b111111.
0x158 tx_txcc_p6post_coef_mult — Preset 6 post emphasis coefficient multiplier value register
  [31:16] tx_txcc_p6post_coef_mult_31_16 ro — Reserved
  [15:8] tx_txcc_p6post_coef_mult_15_8 ro — Reserved
  [7:0] tx_txcc_p6post_coef_mult_7_0 — Note: The output of the multiplier is 6 bits wide. It is possible to set the multiplier value here to a sufficiently large value to cause the multiplier result to be such that it can't be represented by a 6 bit value. In such a case, the multiplier output will be driven to 6'b111111.
0x15C tx_txcc_p7post_coef_mult reset 0x19 — Preset 7 post emphasis coefficient multiplier value register
  [31:16] tx_txcc_p7post_coef_mult_31_16 ro — Reserved
  [15:8] tx_txcc_p7post_coef_mult_15_8 ro — Reserved
  [7:0] tx_txcc_p7post_coef_mult_7_0 — Note: The output of the multiplier is 6 bits wide. It is possible to set the multiplier value here to a sufficiently large value to cause the multiplier result to be such that it can't be represented by a 6 bit value. In such a case, the multiplier output will be driven to 6'b111111.
0x160 tx_txcc_p8post_coef_mult reset 0x10 — Preset 8 post emphasis coefficient multiplier value register
  [31:16] tx_txcc_p8post_coef_mult_31_16 ro — Reserved
  [15:8] tx_txcc_p8post_coef_mult_15_8 ro — Reserved
  [7:0] tx_txcc_p8post_coef_mult_7_0 — Note: The output of the multiplier is 6 bits wide. It is possible to set the multiplier value here to a sufficiently large value to cause the multiplier result to be such that it can't be represented by a 6 bit value. In such a case, the multiplier output will be driven to 6'b111111.
0x164 tx_txcc_p9post_coef_mult — Preset 9 post emphasis coefficient multiplier value register
  [31:16] tx_txcc_p9post_coef_mult_31_16 ro — Reserved
  [15:8] tx_txcc_p9post_coef_mult_15_8 ro — Reserved
  [7:0] tx_txcc_p9post_coef_mult_7_0 — Note: The output of the multiplier is 6 bits wide. It is possible to set the multiplier value here to a sufficiently large value to cause the multiplier result to be such that it can't be represented by a 6 bit value. In such a case, the multiplier output will be driven to 6'b111111.
0x168 tx_txcc_ipost_coef_value — Init post emphasis coefficient value register
  [31:16] tx_txcc_ipost_coef_value_31_16 ro — Reserved
  [15:6] tx_txcc_ipost_coef_value_15_6 ro — Reserved
  [5:0] tx_txcc_ipost_coef_value_5_0
0x200 xcvr_diag_pwri_tmr reset 0x505 — Transceiver power island control timer register
  [31:16] xcvr_diag_pwri_tmr_31_16 ro — Reserved
  [15:13] xcvr_diag_pwri_tmr_15_13 ro — Reserved
  [12:8] xcvr_diag_pwri_tmr_12_8 — Note: A value of 0 in this field is not valid, and will result in a delay of 1 clock cycle. Note: The value of this field must be the same for all lanes that make up a link.
  [7:5] xcvr_diag_pwri_tmr_7_5 ro — Reserved
  [4:0] xcvr_diag_pwri_tmr_4_0 — Note: A value of 0 in this field is not valid, and will result in a delay of 1 clock cycle. Note: The value of this field must be the same for all lanes that make up a link.
0x204 xcvr_diag_xcal_pwri_ovrd reset 0x424 — Note: This register must not be part of any register read write test where patterns other than those described in this register are written to this register.
  [31:16] xcvr_diag_xcal_pwri_ovrd_31_16 ro — Reserved
  [15] xcvr_diag_xcal_pwri_ovrd_15
  [14] xcvr_diag_xcal_pwri_ovrd_14
  [13:12] xcvr_diag_xcal_pwri_ovrd_13_12 ro — Reserved
  [11] xcvr_diag_xcal_pwri_ovrd_11
  [10] xcvr_diag_xcal_pwri_ovrd_10 ro
  [9] xcvr_diag_xcal_pwri_ovrd_9
  [8] xcvr_diag_xcal_pwri_ovrd_8 ro
  [7:0] xcvr_diag_xcal_pwri_ovrd_7_0 — Note: The value of this field must be the same for all lanes that make up a link.
0x208 xcvr_diag_xcal_pwri_stat reset 0x24 — Transceiver transceiver calibration power island control status register
  [31:16] xcvr_diag_xcal_pwri_stat_31_16 ro — Reserved
  [15:8] xcvr_diag_xcal_pwri_stat_15_8 ro — Reserved
  [7:0] xcvr_diag_xcal_pwri_stat_7_0 ro
0x20C xcvr_diag_xdp_pwri_ovrd reset 0x424 — Note: This register must not be part of any register read write test where patterns other than those described in this register are written to this register.
  [31:16] xcvr_diag_xdp_pwri_ovrd_31_16 ro — Reserved
  [15] xcvr_diag_xdp_pwri_ovrd_15
  [14] xcvr_diag_xdp_pwri_ovrd_14
  [13:12] xcvr_diag_xdp_pwri_ovrd_13_12 ro — Reserved
  [11] xcvr_diag_xdp_pwri_ovrd_11
  [10] xcvr_diag_xdp_pwri_ovrd_10 ro
  [9] xcvr_diag_xdp_pwri_ovrd_9
  [8] xcvr_diag_xdp_pwri_ovrd_8 ro
  [7:0] xcvr_diag_xdp_pwri_ovrd_7_0
0x210 xcvr_diag_xdp_pwri_stat reset 0x24 — Transceiver transceiver data path power island control status register
  [31:16] xcvr_diag_xdp_pwri_stat_31_16 ro — Reserved
  [15:8] xcvr_diag_xdp_pwri_stat_15_8 ro — Reserved
  [7:0] xcvr_diag_xdp_pwri_stat_7_0 ro
0x214 xcvr_diag_plldrc_ctrl reset 0x56 — Transceiver PLL data rate clock control register
  [31:16] xcvr_diag_plldrc_ctrl_31_16 ro — Reserved
  [15:14] xcvr_diag_plldrc_ctrl_15_14
  [13:12] xcvr_diag_plldrc_ctrl_13_12
  [11:10] xcvr_diag_plldrc_ctrl_11_10
  [9:8] xcvr_diag_plldrc_ctrl_9_8
  [7:6] xcvr_diag_plldrc_ctrl_7_6
  [5:4] xcvr_diag_plldrc_ctrl_5_4
  [3:2] xcvr_diag_plldrc_ctrl_3_2
  [1:0] xcvr_diag_plldrc_ctrl_1_0
0x218 xcvr_diag_hsclk_sel — Transceiver high speed clock select register
  [31:16] xcvr_diag_hsclk_sel_31_16 ro — Reserved
  [15:14] xcvr_diag_hsclk_sel_15_14 ro — Reserved
  [13:12] xcvr_diag_hsclk_sel_13_12
  [11:10] xcvr_diag_hsclk_sel_11_10 ro — Reserved
  [9:8] xcvr_diag_hsclk_sel_9_8
  [7:6] xcvr_diag_hsclk_sel_7_6 ro — Reserved
  [5:4] xcvr_diag_hsclk_sel_5_4
  [3:2] xcvr_diag_hsclk_sel_3_2 ro — Reserved
  [1:0] xcvr_diag_hsclk_sel_1_0
0x21C xcvr_diag_hsclk_div reset 0x101 — Transceiver high speed clock divider register
  [31:16] xcvr_diag_hsclk_div_31_16 ro — Reserved
  [15] xcvr_diag_hsclk_div_15 ro — Reserved
  [14:9] xcvr_diag_hsclk_div_14_9 ro — Reserved
  [8] xcvr_diag_hsclk_div_8
  [7:6] xcvr_diag_hsclk_div_7_6
  [5:4] xcvr_diag_hsclk_div_5_4
  [3:2] xcvr_diag_hsclk_div_3_2 — Default value = 2' h01 when in USB3
  [1:0] xcvr_diag_hsclk_div_1_0 — Default value = 2' h10 when in USB3
0x220 xcvr_diag_txclk_ctrl — TX clock control register
  [31:16] xcvr_diag_txclk_ctrl_31_16 ro — Reserved
  [15] xcvr_diag_txclk_ctrl_15 — TX serializer clock invert
  [14:0] xcvr_diag_txclk_ctrl_14_0 ro — Reserved
0x224 xcvr_diag_rxclk_ctrl — RX clock control register
  [31:16] xcvr_diag_rxclk_ctrl_31_16 ro — Reserved
  [15] xcvr_diag_rxclk_ctrl_15 — RX deserializer clock invert
  [14:0] xcvr_diag_rxclk_ctrl_14_0 ro — Reserved
0x228 xcvr_diag_bidi_ctrl — Transceiver control register
  [31:16] xcvr_diag_bidi_ctrl_31_16 ro — Reserved
  [15:2] xcvr_diag_bidi_ctrl_15_2 ro — Reserved
  [1] xcvr_diag_bidi_ctrl_1 — txda_lane_skew_sel : use when in DP low speed mode
  [0] xcvr_diag_bidi_ctrl_0
0x22C xcvr_diag_psc_ovrd reset 0x6 — Power state controller override register
  [31:16] xcvr_diag_psc_ovrd_31_16 ro — Reserved
  [15:5] xcvr_diag_psc_ovrd_15_5 ro — Reserved
  [n] xcvr_diag_psc_ovrd_{n} (n=0..4)
0x230 xcvr_diag_rst_diag — Transceiver control reset diagnostic register
  [31:16] xcvr_diag_rst_diag_31_16 ro — Reserved
  [15:3] xcvr_diag_rst_diag_15_3 ro — Reserved
  [2] xcvr_diag_rst_diag_2 ro — Current state of the tx_coef_calc_reset_n reset.
  [1] xcvr_diag_rst_diag_1 ro — Current state of the xcvr_psm_reset_n reset.
  [0] xcvr_diag_rst_diag_0 ro — Current state of the xcvr_ref_clk_reset_n reset.
0x234 xcvr_diag_xcvr_clk_ctrl — Transceiver clock reset control register
  [31:16] xcvr_diag_xcvr_clk_ctrl_31_16 ro — Reserved
  [15:6] xcvr_diag_xcvr_clk_ctrl_15_6 ro — Reserved
  [5:0] xcvr_diag_xcvr_clk_ctrl_5_0 — Reserved
0x238 xcvr_diag_enb_ana_dcd_test — Transceiver embedded analog decoder test register
  [31:5] xcvr_diag_enb_ana_dcd_test_31_5 — Reserved
  [4] xcvr_diag_enb_ana_dcd_test_4
  [3] xcvr_diag_enb_ana_dcd_test_3
  [2] xcvr_diag_enb_ana_dcd_test_2 — Test chain clock
  [1] xcvr_diag_enb_ana_dcd_test_1 — Test chain input
  [0] xcvr_diag_enb_ana_dcd_test_0 ro — Test chain output
0x280 tx_psc_a0 reset 0x1FF — Transmitter A0 power state definition register
  [31:16] tx_psc_a0_31_16 ro — Reserved
  [15:12] tx_psc_a0_15_12 ro — Reserved
  [11] tx_psc_a0_11 — TX driver common mode enable extend control
  [10] tx_psc_a0_10 — Note: This function is implemented for additional power savings. In the analog, this signal controls a MUX select associated with the driver. Setting this bit to 1'b1 will force the MUX to select the LFPS data path. By selecting this path in low power states, instead of the serializer path, the driver inputs will be driven to 1'b0, instead of having the potential to toggle.
  [9] tx_psc_a0_9 — LFPS clock gate enable
  [8] tx_psc_a0_8 — TX clock enable
  [7] tx_psc_a0_7 — Transmitter low current mode
  [6] tx_psc_a0_6 — TX pre-emphasis enable (C-2):
  [5] tx_psc_a0_5 — TX driver common mode enable
  [4] tx_psc_a0_4 — TX driver enable
  [3] tx_psc_a0_3 — TX post-emphasis enable (C
  [2] tx_psc_a0_2 — TX pre-emphasis enable (C
  [1] tx_psc_a0_1 — TX databuf enable
  [0] tx_psc_a0_0 — TX serializer enable
0x284 tx_psc_a1 reset 0x5EF — Transmitter A1 power state definition register
  [31:16] tx_psc_a1_31_16 ro — Reserved
  [15:12] tx_psc_a1_15_12 ro — Reserved
  [11] tx_psc_a1_11 — TX driver common mode enable extend control
  [10] tx_psc_a1_10 — Force txda_lfps_sel active
  [9] tx_psc_a1_9 — LFPS clock gate enable
  [8] tx_psc_a1_8 — TX clock enable
  [7] tx_psc_a1_7 — Transmitter low current mode
  [6] tx_psc_a1_6 — TX pre-emphasis enable (C
  [5] tx_psc_a1_5 — TX driver common mode enable
  [4] tx_psc_a1_4 — TX driver enable
  [3] tx_psc_a1_3 — TX post-emphasis enable (C
  [2] tx_psc_a1_2 — TX pre-emphasis enable (C
  [1] tx_psc_a1_1 — TX databuf enable
  [0] tx_psc_a1_0 — TX serializer enable
0x288 tx_psc_a2 reset 0x4EE — Transmitter A2 power state definition register
  [31:16] tx_psc_a2_31_16 ro — Reserved
  [15:12] tx_psc_a2_15_12 ro — Reserved
  [11] tx_psc_a2_11 — TX driver common mode enable extend control
  [10] tx_psc_a2_10 — active
  [9] tx_psc_a2_9 — LFPS clock gate enable
  [8] tx_psc_a2_8 — TX clock enable
  [7] tx_psc_a2_7 — Transmitter low current mode
  [6] tx_psc_a2_6 — TX pre-emphasis enable (C
  [5] tx_psc_a2_5 — TX driver common mode enable
  [4] tx_psc_a2_4 — TX driver enable
  [3] tx_psc_a2_3 — TX post-emphasis enable (C
  [2] tx_psc_a2_2 — TX pre-emphasis enable (C
  [1] tx_psc_a2_1 — TX databuf enable
  [0] tx_psc_a2_0 — TX serializer enable
0x28C tx_psc_a3 reset 0x4EE — Transmitter A3 power state definition register
  [31:16] tx_psc_a3_31_16 ro — Reserved
  [15:12] tx_psc_a3_15_12 ro — Reserved
  [11] tx_psc_a3_11 — TX driver common mode enable extend control
  [10] tx_psc_a3_10 — Force txda_lfps_sel active
  [9] tx_psc_a3_9 — LFPS clock gate enable
  [8] tx_psc_a3_8 — TX clock enable
  [7] tx_psc_a3_7 — Transmitter low current mode
  [6] tx_psc_a3_6 — TX pre-emphasis enable (C
  [5] tx_psc_a3_5 — TX driver common mode enable
  [4] tx_psc_a3_4 — TX driver enable
  [3] tx_psc_a3_3 — TX post-emphasis enable (C
  [2] tx_psc_a3_2 — TX pre-emphasis enable (C
  [1] tx_psc_a3_1 — TX databuf enable
  [0] tx_psc_a3_0 — TX serializer enable
0x290 tx_psc_a4 reset 0x880 — Transmitter A4 power state definition register
  [31:16] tx_psc_a4_31_16 ro — Reserved
  [15:12] tx_psc_a4_15_12 ro — Reserved
  [11] tx_psc_a4_11 — TX driver common mode enable extend control
  [10] tx_psc_a4_10 — Force txda_lfps_sel active
  [9] tx_psc_a4_9 — LFPS clock gate enable
  [8] tx_psc_a4_8 — TX clock enable
  [7] tx_psc_a4_7 — Transmitter low current mode
  [6] tx_psc_a4_6 — TX pre-emphasis enable (C
  [5] tx_psc_a4_5 — TX driver common mode enable
  [4] tx_psc_a4_4 — TX driver enable
  [3] tx_psc_a4_3 — TX post-emphasis enable (C
  [2] tx_psc_a4_2 — TX pre-emphasis enable (C
  [1] tx_psc_a4_1 — TX databuf enable
  [0] tx_psc_a4_0 — TX serializer enable
0x294 tx_psc_a5 — Transmitter A5 power state definition register
  [31:16] tx_psc_a5_31_16 ro — Reserved
  [15:12] tx_psc_a5_15_12 ro — Reserved
  [11] tx_psc_a5_11 — TX driver common mode enable extend control
  [10] tx_psc_a5_10 — Force txda_lfps_sel active
  [9] tx_psc_a5_9 — LFPS clock gate enable
  [8] tx_psc_a5_8 — TX clock enable
  [7] tx_psc_a5_7 — Transmitter low current mode
  [6] tx_psc_a5_6 — TX pre-emphasis enable (C
  [5] tx_psc_a5_5 — TX driver common mode enable
  [4] tx_psc_a5_4 — TX driver enable
  [3] tx_psc_a5_3 — TX post-emphasis enable (C
  [2] tx_psc_a5_2 — TX pre-emphasis enable (C
  [1] tx_psc_a5_1 — TX databuf enable
  [0] tx_psc_a5_0 — TX serializer enable
0x298 tx_psc_cal reset 0x1A3 — Transmitter calibration power state definition register
  [31:16] tx_psc_cal_31_16 ro — Reserved
  [15:12] tx_psc_cal_15_12 ro — Reserved
  [11] tx_psc_cal_11 — TX driver common mode enable extend control
  [10] tx_psc_cal_10 — Force txda_lfps_sel active
  [9] tx_psc_cal_9 — LFPS clock gate enable
  [8] tx_psc_cal_8 — TX clock enable
  [7] tx_psc_cal_7 — Transmitter low current mode
  [6] tx_psc_cal_6 — TX pre-emphasis enable (C
  [5] tx_psc_cal_5 — TX driver common mode enable
  [4] tx_psc_cal_4 — TX driver enable
  [3] tx_psc_cal_3 — TX post-emphasis enable (C
  [2] tx_psc_cal_2 — TX pre-emphasis enable (C
  [1] tx_psc_cal_1 — TX databuf enable
  [0] tx_psc_cal_0 — TX serializer enable
0x29C tx_psc_rdy reset 0xA0 — Transmitter ready power state definition register
  [31:16] tx_psc_rdy_31_16 ro — Reserved
  [15:12] tx_psc_rdy_15_12 ro — Reserved
  [11] tx_psc_rdy_11 — TX driver common mode enable extend control
  [10] tx_psc_rdy_10 — Force txda_lfps_sel active
  [9] tx_psc_rdy_9 — LFPS clock gate enable
  [8] tx_psc_rdy_8 — TX clock enable
  [7] tx_psc_rdy_7 — Transmitter low current mode
  [6] tx_psc_rdy_6 — TX pre-emphasis enable (C
  [5] tx_psc_rdy_5 — TX driver common mode enable
  [4] tx_psc_rdy_4 — TX driver enable
  [3] tx_psc_rdy_3 — TX post-emphasis enable (C
  [2] tx_psc_rdy_2 — TX pre-emphasis enable (C
  [1] tx_psc_rdy_1 — TX databuf enable
  [0] tx_psc_rdy_0 — TX serializer enable
0x300 tx_rcvdet_ctrl — Transmit receiver detect control register
  [31:16] tx_rcvdet_ctrl_31_16 ro — Reserved
  [15] tx_rcvdet_ctrl_15 — Note: This bit is intended to be for diagnostics purposes only. The receiver detect process must not be under the control of the top level tx_rcv_detect_en pin when attempting to initiate the process using this register.
  [14] tx_rcvdet_ctrl_14 ro — Note: This bit is intended to be for diagnostics purposes only.
  [13] tx_rcvdet_ctrl_13 ro — Receiver detected
  [12:0] tx_rcvdet_ctrl_12_0 ro — Reserved
0x304 tx_rcvdet_ovrd — Transmit receiver detect override register
  [31:16] tx_rcvdet_ovrd_31_16 ro — Reserved
  [15] tx_rcvdet_ovrd_15 — Receiver detect override enable
  [14] tx_rcvdet_ovrd_14
  [13:0] tx_rcvdet_ovrd_13_0 ro — Reserved
0x308 tx_rcvdet_en_tmr — Transmit receiver detect enable timer register
  [31:16] tx_rcvdet_en_tmr_31_16 ro — Reserved
  [15:0] tx_rcvdet_en_tmr_15_0 — Enable wait time value
0x30C tx_rcvdet_st_tmr reset 0x9C4 — Transmit receiver detect start timer register
  [31:16] tx_rcvdet_st_tmr_31_16 ro — Reserved
  [15:0] tx_rcvdet_st_tmr_15_0
0x380 tx_bist_ctrl — Note: This register is on the diagnostic power island, and cannot be written to when this power island is switched off.
  [31:16] tx_bist_ctrl_31_16 ro — Reserved
  [15:12] tx_bist_ctrl_15_12 ro — Reserved
  [11:8] tx_bist_ctrl_11_8
  [7:5] tx_bist_ctrl_7_5 ro — Reserved
  [4] tx_bist_ctrl_4 — Transmitter BIST force error
  [3:2] tx_bist_ctrl_3_2 ro — Reserved
  [1] tx_bist_ctrl_1 wo — Note : This clear function simply resets the FIFO pointers. It does not clear the contents of the FIFO.
  [0] tx_bist_ctrl_0 — Note : The remaining bits in this register must be stable when changing this bit. Therefore, it is best to enable and disable this function using a read / modify / write of this bit.
0x384 tx_bist_uddwr — Note: This register is on the diagnostic power island, and cannot be written to when this power island is switched off.
  [31:16] tx_bist_uddwr_31_16 ro — Reserved
  [15:10] tx_bist_uddwr_15_10 ro — Reserved
  [9:0] tx_bist_uddwr_9_0 wo — Transmitter BIST user defined data
0x388 tx_bist_seed0 reset 0x1 — Note: This register is on the diagnostic power island, and cannot be written to when this power island is switched off.
  [31:16] tx_bist_seed0_31_16 ro — Reserved
  [15:3] tx_bist_seed0_15_3 — Reserved - spare
  [2:0] tx_bist_seed0_2_0 — Note: This register field must never be all 0s.
0x38C tx_bist_seed1 — Note: This register is on the diagnostic power island, and cannot be written to when this power island is switched off.
  [31:16] tx_bist_seed1_31_16 ro — Reserved
  [15] tx_bist_seed1_15 ro — Reserved
  [14:0] tx_bist_seed1_14_0 — Reserved - spare
0x400 tx_duty_cycle_cal_ctrl — TX duty cycle calibration control register
  [31:16] tx_duty_cycle_cal_ctrl_31_16 ro — Reserved
  [15] tx_duty_cycle_cal_ctrl_15
  [14] tx_duty_cycle_cal_ctrl_14 ro — Note: Three cmn_ref_clk cycles are required after the start of the calibration process to clear this signal.
  [13] tx_duty_cycle_cal_ctrl_13 ro — Note: Due to the nature of the calibration process, it is not possible to determine if the analog responded or not for the lowest code of 5'b10001. The reason for this is, when sequencing to lower codes, the calibration function is looking for the analog response to transition from 1'b1 to 1'b0. If the lowest calibration code is the correct code, the analog will respond with 1'b1, and the algorithm can't sequence to a lower code to look for the transition from 1'b1 to 1'b0. Similarly, if the analog is not responding, it is not possible to sequence to a lower code to detect this. Therefore, even when the calibration function selects this calibration code as valid, this bit will be set.
  [12] tx_duty_cycle_cal_ctrl_12 ro
  [11:7] tx_duty_cycle_cal_ctrl_11_7 ro — Reserved
  [6:0] tx_duty_cycle_cal_ctrl_6_0 ro — Note: The reset value for this field is with the common calibration power island switched off. In cases where this power island is switched on, the reset value be 7'b1000000.
0x404 tx_duty_cycle_cal_ovrd — TX duty cycle calibration override register
  [31:16] tx_duty_cycle_cal_ovrd_31_16 ro — Reserved
  [15] tx_duty_cycle_cal_ovrd_15 — Note: The value of this field must not be changed while the calibration function is running.
  [14] tx_duty_cycle_cal_ovrd_14 — Note: The value of this field must not be changed while the calibration function is running.
  [13:7] tx_duty_cycle_cal_ovrd_13_7 ro — Reserved
  [6:0] tx_duty_cycle_cal_ovrd_6_0
0x408 tx_duty_cycle_cal_start reset 0x40 — TX duty cycle calibration start register
  [31:16] tx_duty_cycle_cal_start_31_16 ro — Reserved
  [15] tx_duty_cycle_cal_start_15
  [14:7] tx_duty_cycle_cal_start_14_7 ro — Reserved
  [6:0] tx_duty_cycle_cal_start_6_0 — Note that this is always a positive number,from 2 to 127.
0x40C tx_duty_cycle_cal_tune — TX duty cycle calibration tune register
  [31:16] tx_duty_cycle_cal_tune_31_16 ro — Reserved
  [15:6] tx_duty_cycle_cal_tune_15_6 ro — Reserved
  [5:0] tx_duty_cycle_cal_tune_5_0 — Note: This value is a twos complement value, so the calibrated code can be increased or decreased.
0x410 tx_duty_cycle_cal_init_tmr reset 0x7D — TX duty cycle calibration initialization timer register
  [31:16] tx_duty_cycle_cal_init_tmr_31_16 ro — Reserved
  [15:9] tx_duty_cycle_cal_init_tmr_15_9 ro — Reserved
  [8:0] tx_duty_cycle_cal_init_tmr_8_0 — Note: This results in the minimum number of tx_dc_cal_clk clocks required to wait 5 uSec. Note: This should never be set to a value of less than 1.
0x414 tx_duty_cycle_cal_iter_tmr reset 0x87 — TX duty cycle calibration iteration timer register
  [31:12] tx_duty_cycle_cal_iter_tmr_31_12 ro — Reserved
  [11:9] tx_duty_cycle_cal_iter_tmr_11_9 — DC calibration act range : This signal will drive txda_dc_cal_act_range[2:0] to analog configuration
  [8:0] tx_duty_cycle_cal_iter_tmr_8_0
